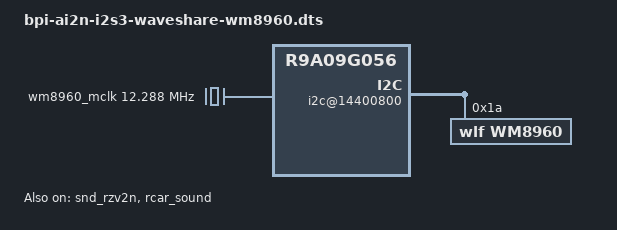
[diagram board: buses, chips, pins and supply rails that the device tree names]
/dts-v1/;
/plugin/;

/ {
	compatible = "renesas,r9a09g056";

	fragment@0 {
		target-path = "/";

		__overlay__ {
			wm8960_mclk: wm8960_mclk {
				compatible = "fixed-clock";
				status = "okay";
				#clock-cells = <0x0>;
				clock-frequency = <0xbb8000>;
			};
		};
	};

	fragment@1 {
		target-path = "/aliases";
		__overlay__ {
			i2c1 = "/soc/i2c@14400800";
		};
	};

	fragment@2 {
		target-path = "/soc/i2c@14400800";
		__overlay__ {
			status = "okay";

			wm8960: wm8960@1a {
		                #sound-dai-cells = <0>;
		                compatible = "wlf,wm8960";
		                reg = <0x1a>;
				status = "okay";
				clocks = <&wm8960_mclk>;
				clock-names = "mclk";
		        };
		};	
	};

	fragment@3 {
		target = <&snd_rzv2n>;
		__overlay__ {
			status = "okay";

			simple-audio-card,widgets =
				"Microphone", "Mic Jack",
				"Speaker", "Speaker",
				"Headphone", "Headphone Jack";

			simple-audio-card,routing =
				"Headphone Jack", "HP_L",
				"Headphone Jack", "HP_R",
				"Speaker", "SPK_LP",
				"Speaker", "SPK_LN",
				"LINPUT1", "Mic Jack",
				"LINPUT3", "Mic Jack",
				"RINPUT1", "Mic Jack",
				"RINPUT2", "Mic Jack";
		};
	};

	fragment@4 {
		target = <&codec_dai>;
		__overlay__ {
			sound-dai = <&wm8960>;
		};
	};

	fragment@5 {
		target = <&rcar_sound>;
		__overlay__ {
			status = "okay";
		};
	};
};
